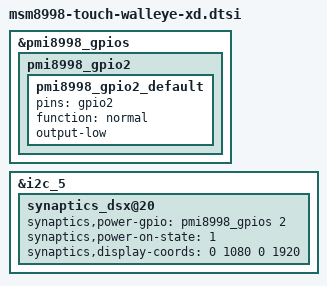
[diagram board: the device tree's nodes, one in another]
#include "msm8998-touch-mw-common.dtsi"

&pmi8998_gpios {
	pmi8998_gpio2 {
		pmi8998_gpio2_default: pmi8998_gpio2_default {
			pins = "gpio2";
			function = "normal";
			output-low;
		};
	};
};

&i2c_5 {
	synaptics_dsx@20 {
		synaptics,power-gpio = <&pmi8998_gpios 2 0>;
		synaptics,power-on-state = <1>;
		synaptics,display-coords = <0 1080 0 1920>;
	};
};
